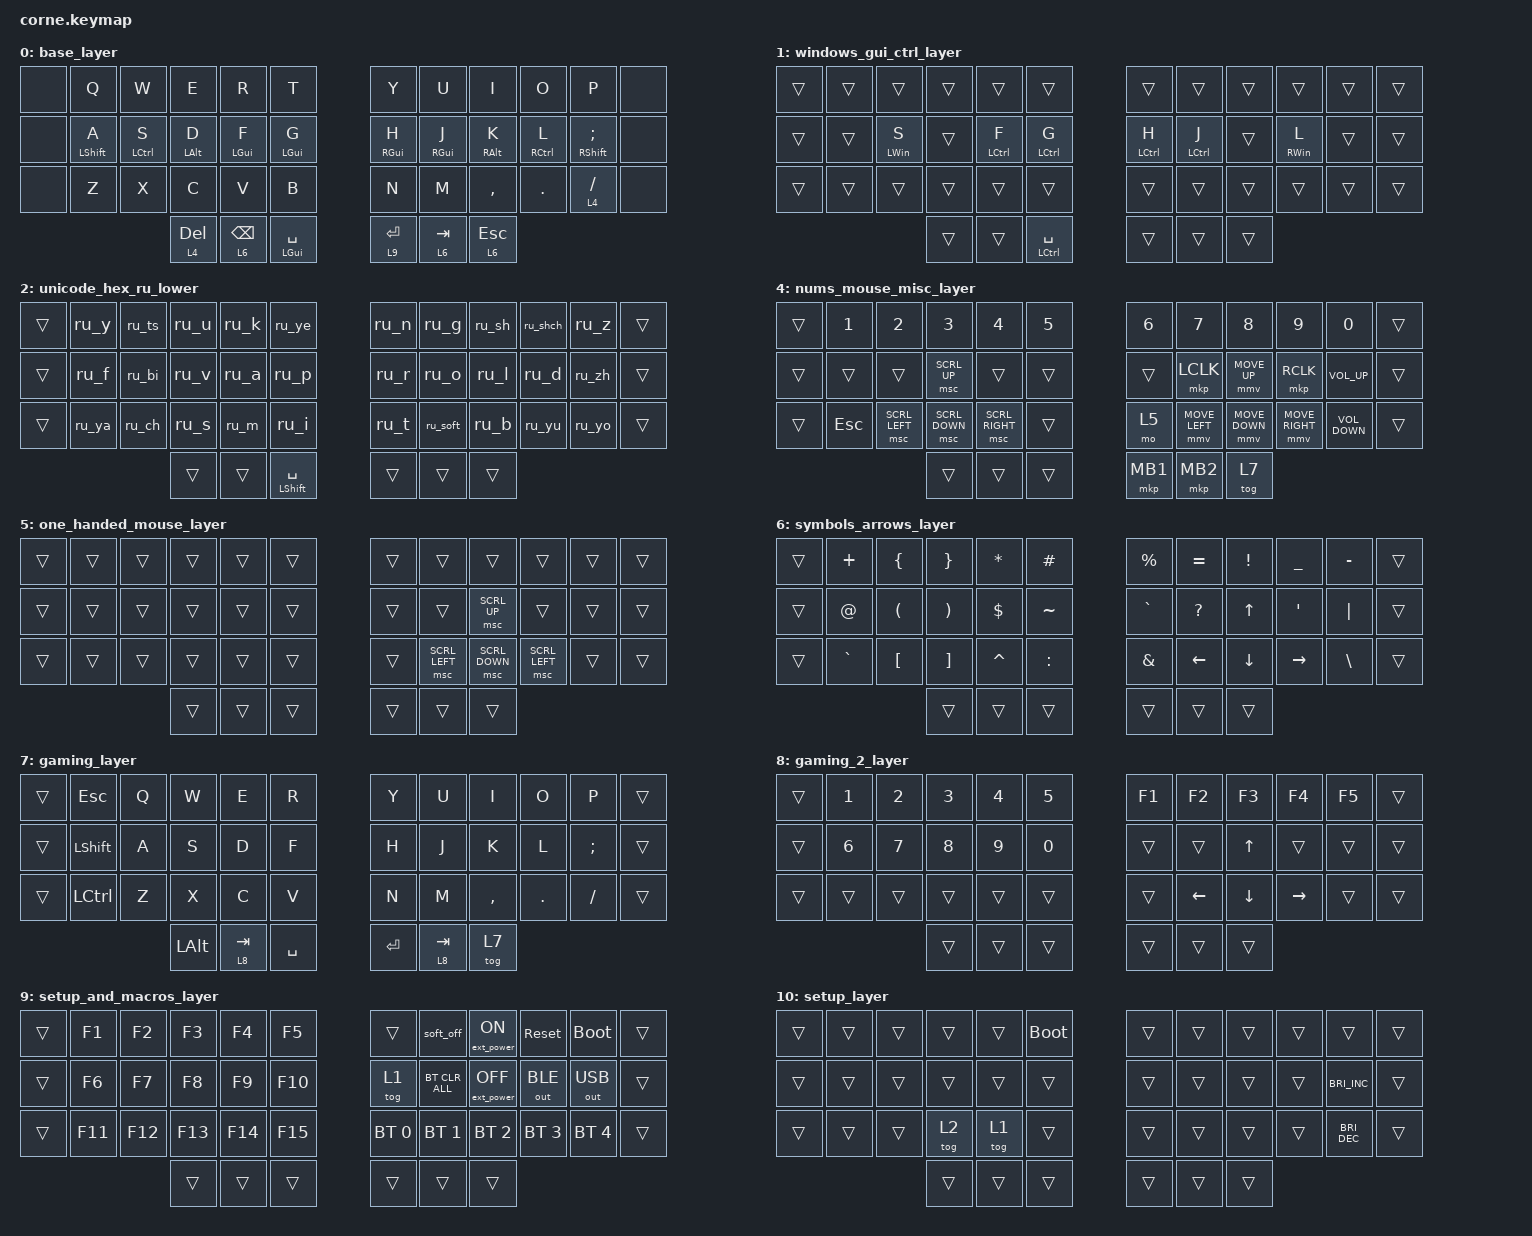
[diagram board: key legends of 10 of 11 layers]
/*
 * Copyright (c) 2020 The ZMK Contributors
 *
 * SPDX-License-Identifier: MIT
 */

#define ZMK_POINTING_DEFAULT_MOVE_VAL 1200  // default: 600
#define ZMK_POINTING_DEFAULT_SCRL_VAL 20   // default: 10
#define HOST_OS 2 /* for the zmk-helpers, MacOS specific unicode hex input */

#include <behaviors.dtsi>
#include <dt-bindings/zmk/bt.h>
#include <dt-bindings/zmk/ext_power.h>
#include <dt-bindings/zmk/keys.h>
#include <dt-bindings/zmk/outputs.h>
#include <dt-bindings/zmk/pointing.h>
#include "zmk-helpers/helper.h"
#include "zmk-helpers/unicode-chars/russian.dtsi"

&mt { flavor = "balanced"; };

&lt { flavor = "balanced"; };

/ {
    macros {
        unicode_ru_i_kratkaya_lc: unicode_ru_i_kratkaya_lc {
            compatible = "zmk,behavior-macro";
            #binding-cells = <0>;
            wait-ms = <5>;
            tap-ms = <5>;
            bindings =
                <&macro_press>,
                <&kp LALT>,
                <&macro_tap>,
                <&kp KP_N0 &kp KP_N4 &kp KP_N3 &kp KP_N9>,
                <&macro_release>,
                <&kp LALT>;

            label = "й";
        };

        unicode_ru_ts_lc: unicode_ru_ts_lc {
            compatible = "zmk,behavior-macro";
            #binding-cells = <0>;
            wait-ms = <5>;
            tap-ms = <5>;
            bindings =
                <&macro_press>,
                <&kp LALT>,
                <&macro_tap>,
                <&kp KP_N0 &kp KP_N4 &kp KP_N4 &kp KP_N6>,
                <&macro_release>,
                <&kp LALT>;

            label = "ц";
        };

        unicode_ru_u_lc: unicode_ru_u_lc {
            compatible = "zmk,behavior-macro";
            #binding-cells = <0>;
            wait-ms = <5>;
            tap-ms = <5>;
            bindings =
                <&macro_press>,
                <&kp LALT>,
                <&macro_tap>,
                <&kp KP_N0 &kp KP_N4 &kp KP_N4 &kp KP_N3>,
                <&macro_release>,
                <&kp LALT>;

            label = "у";
        };

        unicode_ru_k_lc: unicode_ru_k_lc {
            compatible = "zmk,behavior-macro";
            #binding-cells = <0>;
            wait-ms = <5>;
            tap-ms = <5>;
            bindings =
                <&macro_press>,
                <&kp LALT>,
                <&macro_tap>,
                <&kp KP_N0 &kp KP_N4 &kp KP_N3 &kp A>,
                <&macro_release>,
                <&kp LALT>;

            label = "к";
        };

        unicode_ru_e_lc: unicode_ru_e_lc {
            compatible = "zmk,behavior-macro";
            #binding-cells = <0>;
            wait-ms = <5>;
            tap-ms = <5>;
            bindings =
                <&macro_press>,
                <&kp LALT>,
                <&macro_tap>,
                <&kp KP_N0 &kp KP_N4 &kp KP_N3 &kp KP_N5>,
                <&macro_release>,
                <&kp LALT>;

            label = "е";
        };

        unicode_ru_n_lc: unicode_ru_n_lc {
            compatible = "zmk,behavior-macro";
            #binding-cells = <0>;
            wait-ms = <5>;
            tap-ms = <5>;
            bindings =
                <&macro_press>,
                <&kp LALT>,
                <&macro_tap>,
                <&kp KP_N0 &kp KP_N4 &kp KP_N3 &kp D>,
                <&macro_release>,
                <&kp LALT>;

            label = "н";
        };

        unicode_ru_g_lc: unicode_ru_g_lc {
            compatible = "zmk,behavior-macro";
            #binding-cells = <0>;
            wait-ms = <5>;
            tap-ms = <5>;
            bindings =
                <&macro_press>,
                <&kp LALT>,
                <&macro_tap>,
                <&kp KP_N0 &kp KP_N4 &kp KP_N3 &kp KP_N3>,
                <&macro_release>,
                <&kp LALT>;

            label = "г";
        };

        unicode_ru_sh_lc: unicode_ru_sh_lc {
            compatible = "zmk,behavior-macro";
            #binding-cells = <0>;
            wait-ms = <5>;
            tap-ms = <5>;
            bindings =
                <&macro_press>,
                <&kp LALT>,
                <&macro_tap>,
                <&kp KP_N0 &kp KP_N4 &kp KP_N4 &kp KP_N8>,
                <&macro_release>,
                <&kp LALT>;

            label = "ш";
        };

        unicode_ru_shch_lc: unicode_ru_shch_lc {
            compatible = "zmk,behavior-macro";
            #binding-cells = <0>;
            wait-ms = <5>;
            tap-ms = <5>;
            bindings =
                <&macro_press>,
                <&kp LALT>,
                <&macro_tap>,
                <&kp KP_N0 &kp KP_N4 &kp KP_N4 &kp KP_N9>,
                <&macro_release>,
                <&kp LALT>;

            label = "щ";
        };

        unicode_ru_z_lc: unicode_ru_z_lc {
            compatible = "zmk,behavior-macro";
            #binding-cells = <0>;
            wait-ms = <5>;
            tap-ms = <5>;
            bindings =
                <&macro_press>,
                <&kp LALT>,
                <&macro_tap>,
                <&kp KP_N0 &kp KP_N4 &kp KP_N3 &kp KP_N7>,
                <&macro_release>,
                <&kp LALT>;

            label = "з";
        };

        unicode_ru_kh_lc: unicode_ru_kh_lc {
            compatible = "zmk,behavior-macro";
            #binding-cells = <0>;
            wait-ms = <5>;
            tap-ms = <5>;
            bindings =
                <&macro_press>,
                <&kp LALT>,
                <&macro_tap>,
                <&kp KP_N0 &kp KP_N4 &kp KP_N4 &kp KP_N5>,
                <&macro_release>,
                <&kp LALT>;

            label = "х";
        };

        unicode_ru_tvjordii_znak_lc: unicode_ru_tvjordii_znak_lc {
            compatible = "zmk,behavior-macro";
            #binding-cells = <0>;
            wait-ms = <5>;
            tap-ms = <5>;
            bindings =
                <&macro_press>,
                <&kp LALT>,
                <&macro_tap>,
                <&kp KP_N0 &kp KP_N4 &kp KP_N4 &kp A>,
                <&macro_release>,
                <&kp LALT>;

            label = "ъ";
        };

        unicode_ru_f_lc: unicode_ru_f_lc {
            compatible = "zmk,behavior-macro";
            #binding-cells = <0>;
            wait-ms = <5>;
            tap-ms = <5>;
            bindings =
                <&macro_press>,
                <&kp LALT>,
                <&macro_tap>,
                <&kp KP_N0 &kp KP_N4 &kp KP_N4 &kp KP_N4>,
                <&macro_release>,
                <&kp LALT>;

            label = "ф";
        };

        unicode_ru_y_lc: unicode_ru_y_lc {
            compatible = "zmk,behavior-macro";
            #binding-cells = <0>;
            wait-ms = <5>;
            tap-ms = <5>;
            bindings =
                <&macro_press>,
                <&kp LALT>,
                <&macro_tap>,
                <&kp KP_N0 &kp KP_N4 &kp KP_N4 &kp B>,
                <&macro_release>,
                <&kp LALT>;

            label = "ы";
        };

        unicode_ru_v_lc: unicode_ru_v_lc {
            compatible = "zmk,behavior-macro";
            #binding-cells = <0>;
            wait-ms = <5>;
            tap-ms = <5>;
            bindings =
                <&macro_press>,
                <&kp LALT>,
                <&macro_tap>,
                <&kp KP_N0 &kp KP_N4 &kp KP_N3 &kp KP_N2>,
                <&macro_release>,
                <&kp LALT>;

            label = "в";
        };

        unicode_ru_a_lc: unicode_ru_a_lc {
            compatible = "zmk,behavior-macro";
            #binding-cells = <0>;
            wait-ms = <5>;
            tap-ms = <5>;
            bindings =
                <&macro_press>,
                <&kp LALT>,
                <&macro_tap>,
                <&kp KP_N0 &kp KP_N4 &kp KP_N3 &kp KP_N0>,
                <&macro_release>,
                <&kp LALT>;

            label = "а";
        };

        unicode_ru_p_lc: unicode_ru_p_lc {
            compatible = "zmk,behavior-macro";
            #binding-cells = <0>;
            wait-ms = <5>;
            tap-ms = <5>;
            bindings =
                <&macro_press>,
                <&kp LALT>,
                <&macro_tap>,
                <&kp KP_N0 &kp KP_N4 &kp KP_N3 &kp F>,
                <&macro_release>,
                <&kp LALT>;

            label = "п";
        };

        unicode_ru_r_lc: unicode_ru_r_lc {
            compatible = "zmk,behavior-macro";
            #binding-cells = <0>;
            wait-ms = <5>;
            tap-ms = <5>;
            bindings =
                <&macro_press>,
                <&kp LALT>,
                <&macro_tap>,
                <&kp KP_N0 &kp KP_N4 &kp KP_N4 &kp KP_N0>,
                <&macro_release>,
                <&kp LALT>;

            label = "р";
        };

        unicode_ru_o_lc: unicode_ru_o_lc {
            compatible = "zmk,behavior-macro";
            #binding-cells = <0>;
            wait-ms = <5>;
            tap-ms = <5>;
            bindings =
                <&macro_press>,
                <&kp LALT>,
                <&macro_tap>,
                <&kp KP_N0 &kp KP_N4 &kp KP_N3 &kp E>,
                <&macro_release>,
                <&kp LALT>;

            label = "о";
        };

        unicode_ru_l_lc: unicode_ru_l_lc {
            compatible = "zmk,behavior-macro";
            #binding-cells = <0>;
            wait-ms = <5>;
            tap-ms = <5>;
            bindings =
                <&macro_press>,
                <&kp LALT>,
                <&macro_tap>,
                <&kp KP_N0 &kp KP_N4 &kp KP_N3 &kp B>,
                <&macro_release>,
                <&kp LALT>;

            label = "л";
        };

        unicode_ru_d_lc: unicode_ru_d_lc {
            compatible = "zmk,behavior-macro";
            #binding-cells = <0>;
            wait-ms = <5>;
            tap-ms = <5>;
            bindings =
                <&macro_press>,
                <&kp LALT>,
                <&macro_tap>,
                <&kp KP_N0 &kp KP_N4 &kp KP_N3 &kp KP_N4>,
                <&macro_release>,
                <&kp LALT>;

            label = "д";
        };

        unicode_ru_zh_lc: unicode_ru_zh_lc {
            compatible = "zmk,behavior-macro";
            #binding-cells = <0>;
            wait-ms = <5>;
            tap-ms = <5>;
            bindings =
                <&macro_press>,
                <&kp LALT>,
                <&macro_tap>,
                <&kp KP_N0 &kp KP_N4 &kp KP_N3 &kp KP_N6>,
                <&macro_release>,
                <&kp LALT>;

            label = "ж";
        };

        unicode_ru_ee_lc: unicode_ru_ee_lc {
            compatible = "zmk,behavior-macro";
            #binding-cells = <0>;
            wait-ms = <5>;
            tap-ms = <5>;
            bindings =
                <&macro_press>,
                <&kp LALT>,
                <&macro_tap>,
                <&kp KP_N0 &kp KP_N4 &kp KP_N4 &kp D>,
                <&macro_release>,
                <&kp LALT>;

            label = "э";
        };

        unicode_ru_yo_lc: unicode_ru_yo_lc {
            compatible = "zmk,behavior-macro";
            #binding-cells = <0>;
            wait-ms = <5>;
            tap-ms = <5>;
            bindings =
                <&macro_press>,
                <&kp LALT>,
                <&macro_tap>,
                <&kp KP_N0 &kp KP_N4 &kp KP_N5 &kp KP_N1>,
                <&macro_release>,
                <&kp LALT>;

            label = "ё";
        };

        unicode_ru_ya_lc: unicode_ru_ya_lc {
            compatible = "zmk,behavior-macro";
            #binding-cells = <0>;
            wait-ms = <5>;
            tap-ms = <5>;
            bindings =
                <&macro_press>,
                <&kp LALT>,
                <&macro_tap>,
                <&kp KP_N0 &kp KP_N4 &kp KP_N4 &kp F>,
                <&macro_release>,
                <&kp LALT>;

            label = "я";
        };

        unicode_ru_ch_lc: unicode_ru_ch_lc {
            compatible = "zmk,behavior-macro";
            #binding-cells = <0>;
            wait-ms = <5>;
            tap-ms = <5>;
            bindings =
                <&macro_press>,
                <&kp LALT>,
                <&macro_tap>,
                <&kp KP_N0 &kp KP_N4 &kp KP_N4 &kp KP_N7>,
                <&macro_release>,
                <&kp LALT>;

            label = "ч";
        };

        unicode_ru_s_lc: unicode_ru_s_lc {
            compatible = "zmk,behavior-macro";
            #binding-cells = <0>;
            wait-ms = <5>;
            tap-ms = <5>;
            bindings =
                <&macro_press>,
                <&kp LALT>,
                <&macro_tap>,
                <&kp KP_N0 &kp KP_N4 &kp KP_N4 &kp KP_N1>,
                <&macro_release>,
                <&kp LALT>;

            label = "с";
        };

        unicode_ru_m_lc: unicode_ru_m_lc {
            compatible = "zmk,behavior-macro";
            #binding-cells = <0>;
            wait-ms = <5>;
            tap-ms = <5>;
            bindings =
                <&macro_press>,
                <&kp LALT>,
                <&macro_tap>,
                <&kp KP_N0 &kp KP_N4 &kp KP_N3 &kp C>,
                <&macro_release>,
                <&kp LALT>;

            label = "м";
        };

        unicode_ru_i_lc: unicode_ru_i_lc {
            compatible = "zmk,behavior-macro";
            #binding-cells = <0>;
            wait-ms = <5>;
            tap-ms = <5>;
            bindings =
                <&macro_press>,
                <&kp LALT>,
                <&macro_tap>,
                <&kp KP_N0 &kp KP_N4 &kp KP_N3 &kp KP_N8>,
                <&macro_release>,
                <&kp LALT>;

            label = "и";
        };

        unicode_ru_t_lc: unicode_ru_t_lc {
            compatible = "zmk,behavior-macro";
            #binding-cells = <0>;
            wait-ms = <5>;
            tap-ms = <5>;
            bindings =
                <&macro_press>,
                <&kp LALT>,
                <&macro_tap>,
                <&kp KP_N0 &kp KP_N4 &kp KP_N4 &kp KP_N2>,
                <&macro_release>,
                <&kp LALT>;

            label = "т";
        };

        unicode_ru_myagkii_znak_lc: unicode_ru_myagkii_znak_lc {
            compatible = "zmk,behavior-macro";
            #binding-cells = <0>;
            wait-ms = <5>;
            tap-ms = <5>;
            bindings =
                <&macro_press>,
                <&kp LALT>,
                <&macro_tap>,
                <&kp KP_N0 &kp KP_N4 &kp KP_N4 &kp C>,
                <&macro_release>,
                <&kp LALT>;

            label = "ь";
        };

        unicode_ru_b_lc: unicode_ru_b_lc {
            compatible = "zmk,behavior-macro";
            #binding-cells = <0>;
            wait-ms = <5>;
            tap-ms = <5>;
            bindings =
                <&macro_press>,
                <&kp LALT>,
                <&macro_tap>,
                <&kp KP_N0 &kp KP_N4 &kp KP_N3 &kp KP_N1>,
                <&macro_release>,
                <&kp LALT>;

            label = "б";
        };

        unicode_ru_yu_lc: unicode_ru_yu_lc {
            compatible = "zmk,behavior-macro";
            #binding-cells = <0>;
            wait-ms = <5>;
            tap-ms = <5>;
            bindings =
                <&macro_press>,
                <&kp LALT>,
                <&macro_tap>,
                <&kp KP_N0 &kp KP_N4 &kp KP_N4 &kp E>,
                <&macro_release>,
                <&kp LALT>;

            label = "ю";
        };

        unicode_ru_i_kratkaya_uc: unicode_ru_i_kratkaya_uc {
            compatible = "zmk,behavior-macro";
            #binding-cells = <0>;
            wait-ms = <5>;
            tap-ms = <5>;
            bindings =
                <&macro_press>,
                <&kp LALT>,
                <&macro_tap>,
                <&kp KP_N0 &kp KP_N4 &kp KP_N1 &kp KP_N9>,
                <&macro_release>,
                <&kp LALT>;

            label = "Й";
        };

        unicode_ru_ts_uc: unicode_ru_ts_uc {
            compatible = "zmk,behavior-macro";
            #binding-cells = <0>;
            wait-ms = <5>;
            tap-ms = <5>;
            bindings =
                <&macro_press>,
                <&kp LALT>,
                <&macro_tap>,
                <&kp KP_N0 &kp KP_N4 &kp KP_N2 &kp KP_N6>,
                <&macro_release>,
                <&kp LALT>;

            label = "Ц";
        };

        unicode_ru_u_uc: unicode_ru_u_uc {
            compatible = "zmk,behavior-macro";
            #binding-cells = <0>;
            wait-ms = <5>;
            tap-ms = <5>;
            bindings =
                <&macro_press>,
                <&kp LALT>,
                <&macro_tap>,
                <&kp KP_N0 &kp KP_N4 &kp KP_N2 &kp KP_N3>,
                <&macro_release>,
                <&kp LALT>;

            label = "У";
        };

        unicode_ru_k_uc: unicode_ru_k_uc {
            compatible = "zmk,behavior-macro";
            #binding-cells = <0>;
            wait-ms = <5>;
            tap-ms = <5>;
            bindings =
                <&macro_press>,
                <&kp LALT>,
                <&macro_tap>,
                <&kp KP_N0 &kp KP_N4 &kp KP_N1 &kp A>,
                <&macro_release>,
                <&kp LALT>;

            label = "К";
        };

        unicode_ru_e_uc: unicode_ru_e_uc {
            compatible = "zmk,behavior-macro";
            #binding-cells = <0>;
            wait-ms = <5>;
            tap-ms = <5>;
            bindings =
                <&macro_press>,
                <&kp LALT>,
                <&macro_tap>,
                <&kp KP_N0 &kp KP_N4 &kp KP_N1 &kp KP_N5>,
                <&macro_release>,
                <&kp LALT>;

            label = "Е";
        };

        unicode_ru_n_uc: unicode_ru_n_uc {
            compatible = "zmk,behavior-macro";
            #binding-cells = <0>;
            wait-ms = <5>;
            tap-ms = <5>;
            bindings =
                <&macro_press>,
                <&kp LALT>,
                <&macro_tap>,
                <&kp KP_N0 &kp KP_N4 &kp KP_N1 &kp D>,
                <&macro_release>,
                <&kp LALT>;

            label = "Н";
        };

        unicode_ru_g_uc: unicode_ru_g_uc {
            compatible = "zmk,behavior-macro";
            #binding-cells = <0>;
            wait-ms = <5>;
            tap-ms = <5>;
            bindings =
                <&macro_press>,
                <&kp LALT>,
                <&macro_tap>,
                <&kp KP_N0 &kp KP_N4 &kp KP_N1 &kp KP_N3>,
                <&macro_release>,
                <&kp LALT>;

            label = "Г";
        };

        unicode_ru_sh_uc: unicode_ru_sh_uc {
            compatible = "zmk,behavior-macro";
            #binding-cells = <0>;
            wait-ms = <5>;
            tap-ms = <5>;
            bindings =
                <&macro_press>,
                <&kp LALT>,
                <&macro_tap>,
                <&kp KP_N0 &kp KP_N4 &kp KP_N2 &kp KP_N8>,
                <&macro_release>,
                <&kp LALT>;

            label = "Ш";
        };

        unicode_ru_shch_uc: unicode_ru_shch_uc {
            compatible = "zmk,behavior-macro";
            #binding-cells = <0>;
            wait-ms = <5>;
            tap-ms = <5>;
            bindings =
                <&macro_press>,
                <&kp LALT>,
                <&macro_tap>,
                <&kp KP_N0 &kp KP_N4 &kp KP_N2 &kp KP_N9>,
                <&macro_release>,
                <&kp LALT>;

            label = "Щ";
        };

        unicode_ru_z_uc: unicode_ru_z_uc {
            compatible = "zmk,behavior-macro";
            #binding-cells = <0>;
            wait-ms = <5>;
            tap-ms = <5>;
            bindings =
                <&macro_press>,
                <&kp LALT>,
                <&macro_tap>,
                <&kp KP_N0 &kp KP_N4 &kp KP_N1 &kp KP_N7>,
                <&macro_release>,
                <&kp LALT>;

            label = "З";
        };

        unicode_ru_kh_uc: unicode_ru_kh_uc {
            compatible = "zmk,behavior-macro";
            #binding-cells = <0>;
            wait-ms = <5>;
            tap-ms = <5>;
            bindings =
                <&macro_press>,
                <&kp LALT>,
                <&macro_tap>,
                <&kp KP_N0 &kp KP_N4 &kp KP_N2 &kp KP_N5>,
                <&macro_release>,
                <&kp LALT>;

            label = "Х";
        };

        unicode_ru_tvjordii_znak_uc: unicode_ru_tvjordii_znak_uc {
            compatible = "zmk,behavior-macro";
            #binding-cells = <0>;
            wait-ms = <5>;
            tap-ms = <5>;
            bindings =
                <&macro_press>,
                <&kp LALT>,
                <&macro_tap>,
                <&kp KP_N0 &kp KP_N4 &kp KP_N2 &kp A>,
                <&macro_release>,
                <&kp LALT>;

            label = "Ъ";
        };

        unicode_ru_f_uc: unicode_ru_f_uc {
            compatible = "zmk,behavior-macro";
            #binding-cells = <0>;
            wait-ms = <5>;
            tap-ms = <5>;
            bindings =
                <&macro_press>,
                <&kp LALT>,
                <&macro_tap>,
                <&kp KP_N0 &kp KP_N4 &kp KP_N2 &kp KP_N4>,
                <&macro_release>,
                <&kp LALT>;

            label = "Ф";
        };

        unicode_ru_y_uc: unicode_ru_y_uc {
            compatible = "zmk,behavior-macro";
            #binding-cells = <0>;
            wait-ms = <5>;
            tap-ms = <5>;
            bindings =
                <&macro_press>,
                <&kp LALT>,
                <&macro_tap>,
                <&kp KP_N0 &kp KP_N4 &kp KP_N2 &kp B>,
                <&macro_release>,
                <&kp LALT>;

            label = "Ы";
        };

        unicode_ru_v_uc: unicode_ru_v_uc {
            compatible = "zmk,behavior-macro";
            #binding-cells = <0>;
            wait-ms = <5>;
            tap-ms = <5>;
            bindings =
                <&macro_press>,
                <&kp LALT>,
                <&macro_tap>,
                <&kp KP_N0 &kp KP_N4 &kp KP_N1 &kp KP_N2>,
                <&macro_release>,
                <&kp LALT>;

            label = "В";
        };

        unicode_ru_a_uc: unicode_ru_a_uc {
            compatible = "zmk,behavior-macro";
            #binding-cells = <0>;
            wait-ms = <5>;
            tap-ms = <5>;
            bindings =
                <&macro_press>,
                <&kp LALT>,
                <&macro_tap>,
                <&kp KP_N0 &kp KP_N4 &kp KP_N1 &kp KP_N0>,
                <&macro_release>,
                <&kp LALT>;

            label = "А";
        };

        unicode_ru_p_uc: unicode_ru_p_uc {
            compatible = "zmk,behavior-macro";
            #binding-cells = <0>;
            wait-ms = <5>;
            tap-ms = <5>;
            bindings =
                <&macro_press>,
                <&kp LALT>,
                <&macro_tap>,
                <&kp KP_N0 &kp KP_N4 &kp KP_N1 &kp F>,
                <&macro_release>,
                <&kp LALT>;

            label = "П";
        };

        unicode_ru_r_uc: unicode_ru_r_uc {
            compatible = "zmk,behavior-macro";
            #binding-cells = <0>;
            wait-ms = <5>;
            tap-ms = <5>;
            bindings =
                <&macro_press>,
                <&kp LALT>,
                <&macro_tap>,
                <&kp KP_N0 &kp KP_N4 &kp KP_N2 &kp KP_N0>,
                <&macro_release>,
                <&kp LALT>;

            label = "Р";
        };

        unicode_ru_o_uc: unicode_ru_o_uc {
            compatible = "zmk,behavior-macro";
            #binding-cells = <0>;
            wait-ms = <5>;
            tap-ms = <5>;
            bindings =
                <&macro_press>,
                <&kp LALT>,
                <&macro_tap>,
                <&kp KP_N0 &kp KP_N4 &kp KP_N1 &kp E>,
                <&macro_release>,
                <&kp LALT>;

            label = "О";
        };

        unicode_ru_l_uc: unicode_ru_l_uc {
            compatible = "zmk,behavior-macro";
            #binding-cells = <0>;
            wait-ms = <5>;
            tap-ms = <5>;
            bindings =
                <&macro_press>,
                <&kp LALT>,
                <&macro_tap>,
                <&kp KP_N0 &kp KP_N4 &kp KP_N1 &kp B>,
                <&macro_release>,
                <&kp LALT>;

            label = "Л";
        };

        unicode_ru_d_uc: unicode_ru_d_uc {
            compatible = "zmk,behavior-macro";
            #binding-cells = <0>;
            wait-ms = <5>;
            tap-ms = <5>;
            bindings =
                <&macro_press>,
                <&kp LALT>,
                <&macro_tap>,
                <&kp KP_N0 &kp KP_N4 &kp KP_N1 &kp KP_N4>,
                <&macro_release>,
                <&kp LALT>;

            label = "Д";
        };

        unicode_ru_zh_uc: unicode_ru_zh_uc {
            compatible = "zmk,behavior-macro";
            #binding-cells = <0>;
            wait-ms = <5>;
            tap-ms = <5>;
            bindings =
                <&macro_press>,
                <&kp LALT>,
                <&macro_tap>,
                <&kp KP_N0 &kp KP_N4 &kp KP_N1 &kp KP_N6>,
                <&macro_release>,
                <&kp LALT>;

            label = "Ж";
        };

        unicode_ru_ee_uc: unicode_ru_ee_uc {
            compatible = "zmk,behavior-macro";
            #binding-cells = <0>;
            wait-ms = <5>;
            tap-ms = <5>;
            bindings =
                <&macro_press>,
                <&kp LALT>,
                <&macro_tap>,
                <&kp KP_N0 &kp KP_N4 &kp KP_N2 &kp D>,
                <&macro_release>,
                <&kp LALT>;

            label = "Э";
        };

        unicode_ru_yo_uc: unicode_ru_yo_uc {
            compatible = "zmk,behavior-macro";
            #binding-cells = <0>;
            wait-ms = <5>;
            tap-ms = <5>;
            bindings =
                <&macro_press>,
                <&kp LALT>,
                <&macro_tap>,
                <&kp KP_N0 &kp KP_N4 &kp KP_N0 &kp KP_N1>,
                <&macro_release>,
                <&kp LALT>;

            label = "Ё";
        };

        unicode_ru_ya_uc: unicode_ru_ya_uc {
            compatible = "zmk,behavior-macro";
            #binding-cells = <0>;
            wait-ms = <5>;
            tap-ms = <5>;
            bindings =
                <&macro_press>,
                <&kp LALT>,
                <&macro_tap>,
                <&kp KP_N0 &kp KP_N4 &kp KP_N2 &kp F>,
                <&macro_release>,
                <&kp LALT>;

            label = "Я";
        };

        unicode_ru_ch_uc: unicode_ru_ch_uc {
            compatible = "zmk,behavior-macro";
            #binding-cells = <0>;
            wait-ms = <5>;
            tap-ms = <5>;
            bindings =
                <&macro_press>,
                <&kp LALT>,
                <&macro_tap>,
                <&kp KP_N0 &kp KP_N4 &kp KP_N2 &kp KP_N7>,
                <&macro_release>,
                <&kp LALT>;

            label = "Ч";
        };

        unicode_ru_s_uc: unicode_ru_s_uc {
            compatible = "zmk,behavior-macro";
            #binding-cells = <0>;
            wait-ms = <5>;
            tap-ms = <5>;
            bindings =
                <&macro_press>,
                <&kp LALT>,
                <&macro_tap>,
                <&kp KP_N0 &kp KP_N4 &kp KP_N2 &kp KP_N1>,
                <&macro_release>,
                <&kp LALT>;

            label = "С";
        };

        unicode_ru_m_uc: unicode_ru_m_uc {
            compatible = "zmk,behavior-macro";
            #binding-cells = <0>;
            wait-ms = <5>;
            tap-ms = <5>;
            bindings =
                <&macro_press>,
                <&kp LALT>,
                <&macro_tap>,
                <&kp KP_N0 &kp KP_N4 &kp KP_N1 &kp C>,
                <&macro_release>,
                <&kp LALT>;

            label = "М";
        };

        unicode_ru_i_uc: unicode_ru_i_uc {
            compatible = "zmk,behavior-macro";
            #binding-cells = <0>;
            wait-ms = <5>;
            tap-ms = <5>;
            bindings =
                <&macro_press>,
                <&kp LALT>,
                <&macro_tap>,
                <&kp KP_N0 &kp KP_N4 &kp KP_N1 &kp KP_N8>,
                <&macro_release>,
                <&kp LALT>;

            label = "И";
        };

        unicode_ru_t_uc: unicode_ru_t_uc {
            compatible = "zmk,behavior-macro";
            #binding-cells = <0>;
            wait-ms = <5>;
            tap-ms = <5>;
            bindings =
                <&macro_press>,
                <&kp LALT>,
                <&macro_tap>,
                <&kp KP_N0 &kp KP_N4 &kp KP_N2 &kp KP_N2>,
                <&macro_release>,
                <&kp LALT>;

            label = "Т";
        };

        unicode_ru_myagkii_znak_uc: unicode_ru_myagkii_znak_uc {
            compatible = "zmk,behavior-macro";
            #binding-cells = <0>;
            wait-ms = <5>;
            tap-ms = <5>;
            bindings =
                <&macro_press>,
                <&kp LALT>,
                <&macro_tap>,
                <&kp KP_N0 &kp KP_N4 &kp KP_N2 &kp C>,
                <&macro_release>,
                <&kp LALT>;

            label = "Ь";
        };

        unicode_ru_b_uc: unicode_ru_b_uc {
            compatible = "zmk,behavior-macro";
            #binding-cells = <0>;
            wait-ms = <5>;
            tap-ms = <5>;
            bindings =
                <&macro_press>,
                <&kp LALT>,
                <&macro_tap>,
                <&kp KP_N0 &kp KP_N4 &kp KP_N1 &kp KP_N1>,
                <&macro_release>,
                <&kp LALT>;

            label = "Б";
        };

        unicode_ru_yu_uc: unicode_ru_yu_uc {
            compatible = "zmk,behavior-macro";
            #binding-cells = <0>;
            wait-ms = <5>;
            tap-ms = <5>;
            bindings =
                <&macro_press>,
                <&kp LALT>,
                <&macro_tap>,
                <&kp KP_N0 &kp KP_N4 &kp KP_N2 &kp E>,
                <&macro_release>,
                <&kp LALT>;

            label = "Ю";
        };

        js_arrow_fn_macro: js_arrow_fn_macro {
            compatible = "zmk,behavior-macro";
            #binding-cells = <0>;
            bindings =
                <&macro_tap>,
                <&kp LPAR &kp RPAR &kp EQUAL &kp GT &kp LBRC &kp RBRC &kp LEFT>,
                <&macro_release>;

            label = "JS_ARROW_FN_MACRO";
        };

        js_fn_macro: js_fn_macro {
            compatible = "zmk,behavior-macro";
            #binding-cells = <0>;
            bindings =
                <&macro_tap>,
                <&kp F &kp U &kp N &kp C &kp T &kp I &kp O &kp N &kp SPACE &kp LPAR &kp RPAR &kp LBRC &kp RBRC &kp LEFT>,
                <&macro_release>;

            label = "JS_FN_MACRO";
        };

        js_promise_macro: js_promise_macro {
            compatible = "zmk,behavior-macro";
            #binding-cells = <0>;
            bindings =
                <&macro_tap>,
                <&kp N &kp E &kp W &kp SPACE &kp LS(P) &kp R &kp O &kp M &kp I &kp S &kp E &kp LPAR &kp LPAR &kp R &kp E &kp S &kp COMMA &kp R &kp E &kp J &kp RPAR &kp EQUAL &kp GT &kp R &kp E &kp S &kp LPAR &kp RPAR &kp LEFT_BRACE &kp RBRC &kp RPAR &kp LEFT_ARROW &kp LEFT_ARROW &kp LEFT>,
                <&macro_release>;

            label = "JS_PROMISE_MACRO";
        };

        jsx_useEffect_macro: jsx_useEffect_macro {
            compatible = "zmk,behavior-macro";
            #binding-cells = <0>;
            bindings =
                <&macro_tap>,
                <&kp U &kp S &kp E &kp LS(E) &kp F &kp F &kp E &kp C &kp T &kp LPAR &kp LPAR &kp RPAR &kp EQUAL &kp GT &kp LBRC &kp RBRC &kp COMMA &kp LBKT &kp RIGHT_BRACKET &kp RPAR &kp LEFT &kp LEFT &kp LEFT &kp LEFT &kp LEFT>,
                <&macro_release>;

            label = "JSX_USEEFFECT_MACRO";
        };

        jsx_useState_macro: jsx_useState_macro {
            compatible = "zmk,behavior-macro";
            #binding-cells = <0>;
            bindings =
                <&macro_tap>,
                <&kp C &kp O &kp N &kp S &kp T &kp SPACE &kp LBKT &kp S &kp T &kp A &kp T &kp E &kp COMMA &kp S &kp E &kp T &kp LS(S) &kp T &kp A &kp T &kp E &kp RBKT &kp EQUAL &kp U &kp S &kp E &kp LS(S) &kp T &kp A &kp T &kp E &kp LPAR &kp RPAR &kp LEFT>,
                <&macro_release>;

            label = "JSX_USESTATE_MACRO";
        };

        jsx_useRef_macro: jsx_useRef_macro {
            compatible = "zmk,behavior-macro";
            #binding-cells = <0>;
            bindings =
                <&macro_tap>,
                <&kp C &kp O &kp N &kp S &kp T &kp SPACE &kp R &kp E &kp F &kp EQUAL &kp U &kp S &kp E &kp LS(R) &kp E &kp F &kp LPAR &kp N &kp U &kp L &kp L &kp RPAR>,
                <&macro_release>;

            label = "JSX_USEREF_MACRO";
        };
    };

    combos {
        compatible = "zmk,combos";

        combo_zx_toggle_setup_layer {
            bindings = <&mo 10>;
            key-positions = <25 26>;
        };

        combo_caps_word_on_shifts {
            bindings = <&caps_word_symb_behavior>;
            key-positions = <13 22>;
        };
    };

    behaviors {
        caps_word_symb_behavior: caps_word_symb_behavior {
            compatible = "zmk,behavior-caps-word";
            label = "CAPS_WORD_SYMB_BEHAVIOR";
            #binding-cells = <0>;
            continue-list = <UNDERSCORE BACKSPACE>;
        };
    };

    keymap {
        compatible = "zmk,keymap";

        base_layer {
            bindings = <
&none  &kp Q             &kp W               &kp E           &kp R            &kp T             &kp Y            &kp U            &kp I       &kp O                &kp P                 &none
&none  &mt LEFT_SHIFT A  &mt LEFT_CONTROL S  &mt LEFT_ALT D  &mt LEFT_GUI F   &mt LEFT_GUI G    &mt RIGHT_GUI H  &mt RIGHT_GUI J  &mt RALT K  &mt RIGHT_CONTROL L  &mt RIGHT_SHIFT SEMI  &none
&none  &kp Z             &kp X               &kp C           &kp V            &kp B             &kp N            &kp M            &kp COMMA   &kp DOT              &lt 4 FSLH            &none
                                             &lt 4 DELETE    &lt 6 BACKSPACE  &mt LGUI SPACE    &lt 9 ENTER      &lt 6 TAB        &lt 6 ESC
            >;
        };

        windows_gui_ctrl_layer {
            bindings = <
&trans  &trans  &trans          &trans  &trans       &trans             &trans       &trans       &trans  &trans      &trans  &trans
&trans  &trans  &mt LEFT_WIN S  &trans  &mt LCTRL F  &mt LCTRL G        &mt LCTRL H  &mt LCTRL J  &trans  &mt RWIN L  &trans  &trans
&trans  &trans  &trans          &trans  &trans       &trans             &trans       &trans       &trans  &trans      &trans  &trans
                                &trans  &trans       &mt LCTRL SPACE    &trans       &trans       &trans
            >;
        };

        unicode_hex_ru_lower {
            bindings = <
&trans  &ru_y   &ru_ts  &ru_u   &ru_k   &ru_ye                  &ru_n   &ru_g     &ru_sh  &ru_shch  &ru_z   &trans
&trans  &ru_f   &ru_bi  &ru_v   &ru_a   &ru_p                   &ru_r   &ru_o     &ru_l   &ru_d     &ru_zh  &trans
&trans  &ru_ya  &ru_ch  &ru_s   &ru_m   &ru_i                   &ru_t   &ru_soft  &ru_b   &ru_yu    &ru_yo  &trans
                        &trans  &trans  &mt LEFT_SHIFT SPACE    &trans  &trans    &trans
            >;
        };

        unicode_hex_ru_uc {
            bindings = <
&trans  &unicode_ru_i_kratkaya_uc  &unicode_ru_ts_uc  &unicode_ru_u_uc  &unicode_ru_k_uc  &unicode_ru_e_uc    &unicode_ru_n_uc  &unicode_ru_g_uc             &unicode_ru_sh_uc  &unicode_ru_shch_uc  &unicode_ru_z_uc   &trans
&trans  &unicode_ru_f_uc           &unicode_ru_y_uc   &unicode_ru_v_uc  &unicode_ru_a_uc  &unicode_ru_p_uc    &unicode_ru_r_uc  &unicode_ru_o_uc             &unicode_ru_l_uc   &unicode_ru_d_uc     &unicode_ru_zh_uc  &trans
&trans  &unicode_ru_ya_uc          &unicode_ru_ch_uc  &unicode_ru_s_uc  &unicode_ru_m_uc  &unicode_ru_i_uc    &unicode_ru_t_uc  &unicode_ru_myagkii_znak_uc  &unicode_ru_b_uc   &unicode_ru_yu_uc    &trans             &trans
                                                      &trans            &trans            &mt LCTRL SPACE     &trans            &trans
            >;
        };

        nums_mouse_misc_layer {
            bindings = <
&trans  &kp N1      &kp N2          &kp N3          &kp N4           &kp N5    &kp N6    &kp N7          &kp N8          &kp N9           &kp N0             &trans
&trans  &trans      &trans          &msc SCRL_UP    &trans           &trans    &trans    &mkp LCLK       &mmv MOVE_UP    &mkp RCLK        &kp C_VOL_UP       &trans
&trans  &kp ESCAPE  &msc SCRL_LEFT  &msc SCRL_DOWN  &msc SCRL_RIGHT  &trans    &mo 5     &mmv MOVE_LEFT  &mmv MOVE_DOWN  &mmv MOVE_RIGHT  &kp C_VOLUME_DOWN  &trans
                                    &trans          &trans           &trans    &mkp MB1  &mkp MB2        &tog 7
            >;
        };

        one_handed_mouse_layer {
            bindings = <
&trans  &trans  &trans  &trans  &trans  &trans    &trans  &trans          &trans          &trans          &trans  &trans
&trans  &trans  &trans  &trans  &trans  &trans    &trans  &trans          &msc SCRL_UP    &trans          &trans  &trans
&trans  &trans  &trans  &trans  &trans  &trans    &trans  &msc SCRL_LEFT  &msc SCRL_DOWN  &msc SCRL_LEFT  &trans  &trans
                        &trans  &trans  &trans    &trans  &trans          &trans
            >;
        };

        symbols_arrows_layer {
            bindings = <
&trans  &kp PLUS   &kp LEFT_BRACE        &kp RIGHT_BRACE        &kp ASTERISK  &kp HASH     &kp PRCNT  &kp EQUAL     &kp EXCL  &kp UNDER  &kp MINUS  &trans
&trans  &kp AT     &kp LEFT_PARENTHESIS  &kp RIGHT_PARENTHESIS  &kp DOLLAR    &kp TILDE    &kp GRAVE  &kp QUESTION  &kp UP    &kp SQT    &kp PIPE   &trans
&trans  &kp GRAVE  &kp LBKT              &kp RBKT               &kp CARET     &kp COLON    &kp AMPS   &kp LEFT      &kp DOWN  &kp RIGHT  &kp BSLH   &trans
                                         &trans                 &trans        &trans       &trans     &trans        &trans
            >;
        };

        gaming_layer {
            bindings = <
&trans  &kp ESC           &kp Q  &kp W         &kp E      &kp R        &kp Y      &kp U      &kp I      &kp O    &kp P     &trans
&trans  &kp LEFT_SHIFT    &kp A  &kp S         &kp D      &kp F        &kp H      &kp J      &kp K      &kp L    &kp SEMI  &trans
&trans  &kp LEFT_CONTROL  &kp Z  &kp X         &kp C      &kp V        &kp N      &kp M      &kp COMMA  &kp DOT  &kp FSLH  &trans
                                 &kp LEFT_ALT  &lt 8 TAB  &kp SPACE    &kp ENTER  &lt 8 TAB  &tog 7
            >;
        };

        gaming_2_layer {
            bindings = <
&trans  &kp N1  &kp N2  &kp N3  &kp N4  &kp N5    &kp F1  &kp F2    &kp F3        &kp F4     &kp F5  &trans
&trans  &kp N6  &kp N7  &kp N8  &kp N9  &kp N0    &trans  &trans    &kp UP_ARROW  &trans     &trans  &trans
&trans  &trans  &trans  &trans  &trans  &trans    &trans  &kp LEFT  &kp DOWN      &kp RIGHT  &trans  &trans
                        &trans  &trans  &trans    &trans  &trans    &trans
            >;
        };

        setup_and_macros_layer {
            bindings = <
&trans  &kp F1   &kp F2   &kp F3   &kp F4   &kp F5     &trans        &soft_off       &ext_power EP_ON   &sys_reset    &bootloader   &trans
&trans  &kp F6   &kp F7   &kp F8   &kp F9   &kp F10    &tog 1        &bt BT_CLR_ALL  &ext_power EP_OFF  &out OUT_BLE  &out OUT_USB  &trans
&trans  &kp F11  &kp F12  &kp F13  &kp F14  &kp F15    &bt BT_SEL 0  &bt BT_SEL 1    &bt BT_SEL 2       &bt BT_SEL 3  &bt BT_SEL 4  &trans
                          &trans   &trans   &trans     &trans        &trans          &trans
            >;
        };

        setup_layer {
            bindings = <
&trans  &trans  &trans  &trans  &trans  &bootloader    &trans  &trans  &trans  &trans  &trans                &trans
&trans  &trans  &trans  &trans  &trans  &trans         &trans  &trans  &trans  &trans  &kp C_BRIGHTNESS_INC  &trans
&trans  &trans  &trans  &tog 2  &tog 1  &trans         &trans  &trans  &trans  &trans  &kp C_BRIGHTNESS_DEC  &trans
                        &trans  &trans  &trans         &trans  &trans  &trans
            >;
        };
    };
};
